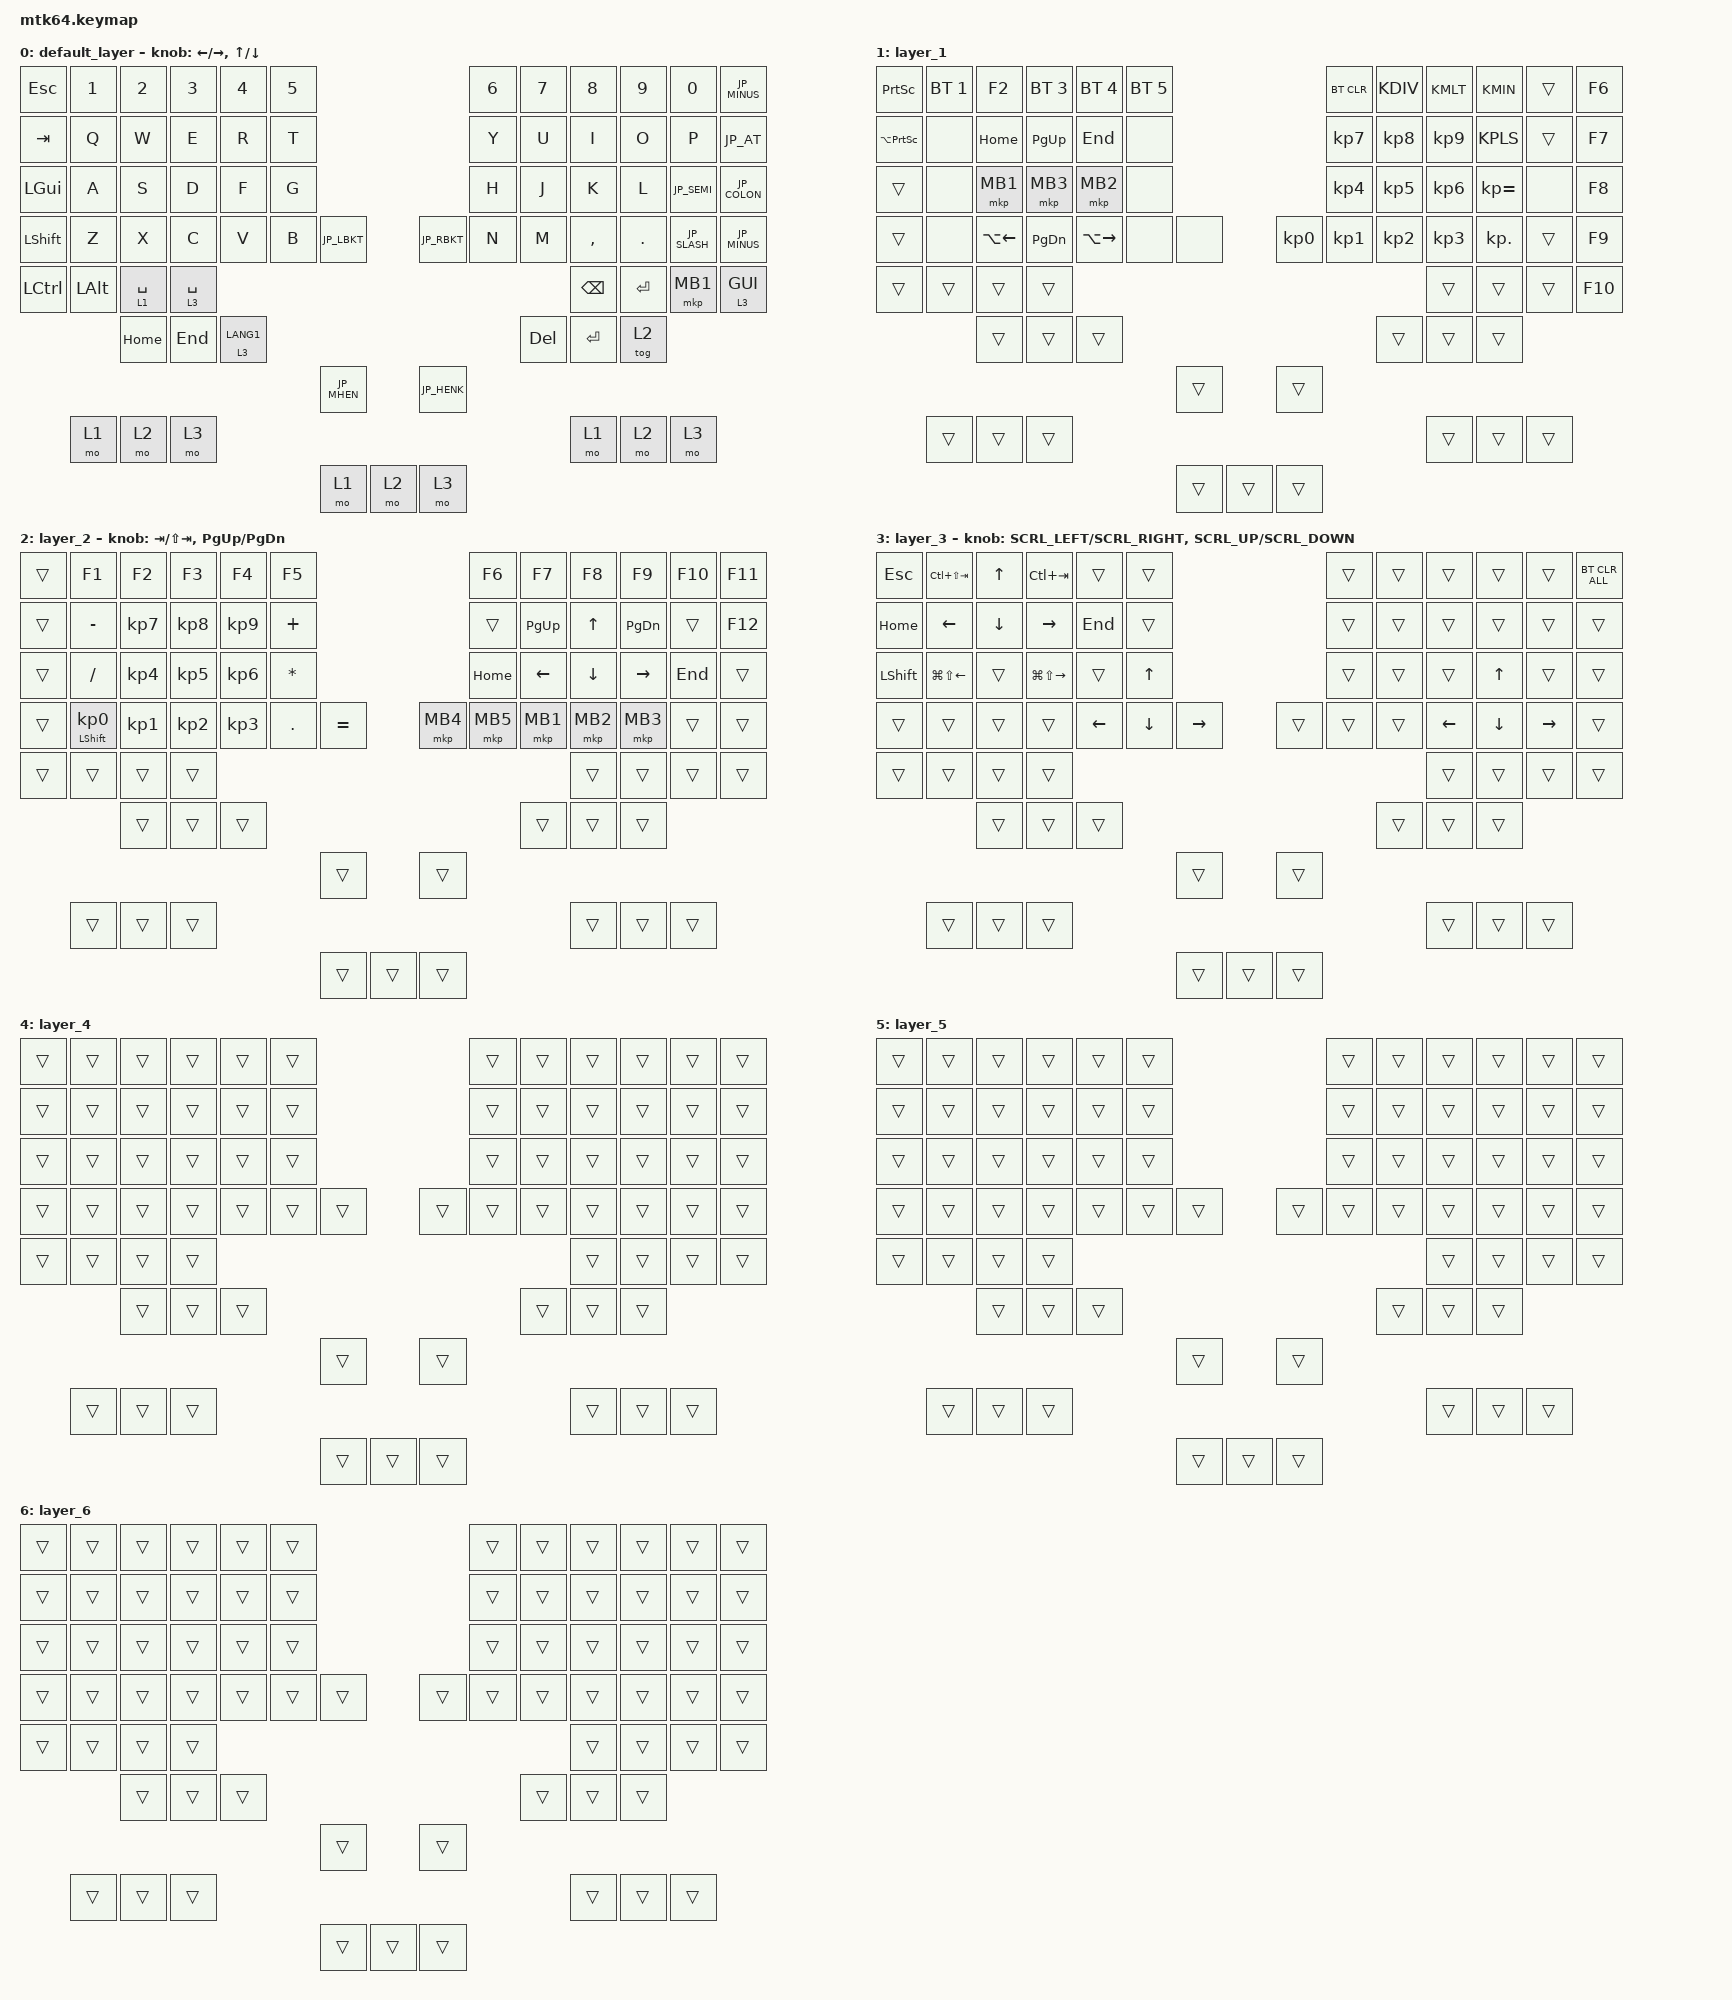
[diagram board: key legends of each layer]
#include <behaviors.dtsi>
#include <dt-bindings/zmk/bt.h>
#include <dt-bindings/zmk/keys.h>
#include <dt-bindings/zmk/pointing.h>
#include <input/processors.dtsi>
#include "keycode_japanese.h"

// スクロール量の設定
#undef ZMK_POINTING_DEFAULT_SCRL_VAL
#define ZMK_POINTING_DEFAULT_SCRL_VAL 60

&mt {
    flavor = "balanced";
    quick-tap-ms = <0>;
};

/*
&mkp_input_listener {
    input-processors = <&zip_temp_layer 6 5000>;
};
*/

/ {
    behaviors {
        // 垂直スクロール用のbehaviorの設定
        scroll_up_down: behavior_sensor_rotate_mouse_wheel_up_down {
            compatible = "zmk,behavior-sensor-rotate-var";
            #sensor-binding-cells = <2>;
            bindings = <&msc>, <&msc>;
            tap-ms = <20>; // スクロールのタップ時間
        };
        // 水平スクロール用のbehaviorの設定
        scroll_left_right: behavior_sensor_rotate_mouse_wheel_left_right {
            compatible = "zmk,behavior-sensor-rotate-var";
            #sensor-binding-cells = <2>;
            bindings = <&msc>, <&msc>;
            tap-ms = <20>; // スクロールのタップ時間
        };
    };
};

/ {

    keymap {
        compatible = "zmk,keymap";

        default_layer {
            bindings = <
&kp ESC   &kp N1 &kp N2 &kp N3   &kp N4   &kp N5                                &kp N6 &kp N7   &kp N8    &kp N9  &kp N0       &kp JP_MINUS
&kp TAB   &kp Q  &kp W  &kp E    &kp R    &kp T                                 &kp Y  &kp U    &kp I     &kp O   &kp P        &kp JP_AT
&kp LGUI &kp A  &kp S  &kp D    &kp F    &kp G                                 &kp H  &kp J    &kp K     &kp L   &kp JP_SEMI  &kp JP_COLON
&kp LSHFT &kp Z  &kp X  &kp C    &kp V    &kp B  &kp JP_LBKT        &kp JP_RBKT &kp N  &kp M    &kp COMMA &kp DOT &kp JP_SLASH &kp JP_MINUS
&kp LCTRL  &kp LALT               &lt 1 SPACE     &lt 3 SPACE        &kp BSPC    &kp ENTER                         &mkp MB1 &lt 3 GUI
                 &kp HOME &kp END                &lt 3 LANG1        &kp DEL                 &kp ENTER &tog 2
                                                 &kp JP_MHEN          &kp JP_HENK
          &mo 1  &mo 2  &mo 3                                                                   &mo 1     &mo 2   &mo 3
                                                 &mo 1    &mo 2     &mo 3  
            >;

            sensor-bindings = <
                &inc_dec_kp LEFT_ARROW RIGHT_ARROW
                &inc_dec_kp UP_ARROW   DOWN_ARROW
            >;
        };

        layer_1 {
            bindings = <
&kp PRINTSCREEN  &bt BT_SEL 1  &kp F2  &bt BT_SEL 3  &bt BT_SEL 4  &bt BT_SEL 5
                                                                    &bt BT_CLR  &kp KDIV  &kp KMLT  &kp KMIN  &trans  &kp F6
&kp LA(PRINTSCREEN)  &none                   &kp HOME  &kp PG_UP  &kp END  &none                                    &kp KP_N7            &kp KP_N8          &kp KP_N9    &kp KPLS             &trans                &kp F7  
&trans  &none                   &mkp MB1  &mkp MB3  &mkp MB2  &none                                &kp KP_N4          &kp KP_N5     &kp KP_N6  &kp KP_EQUAL       &none               &kp F8  
&trans  &none  &kp LA(LEFT)  &kp PG_DN  &kp LA(RIGHT)  &none    &none      &kp KP_N0       &kp KP_N1          &kp KP_N2           &kp KP_N3        &kp KP_DOT              &trans                &kp F9  
&trans  &trans                                                                         &trans        &trans         &trans         &trans                                                                     &trans                &kp F10
                                    &trans           &trans                                          &trans         &trans                                              &trans          &trans
                                                                                                     &trans         &trans
        &trans                      &trans           &trans                                                                                                             &trans          &trans                &trans
                                                                                                     &trans &trans  &trans 
            >;
        };

        layer_2 {
            bindings = <
&trans  &kp F1                      &kp F2           &kp F3           &kp F4           &kp F5                                      &kp F6            &kp F7             &kp F8          &kp F9                &kp F10               &kp F11
&trans  &kp MINUS                   &kp KP_NUMBER_7  &kp KP_NUMBER_8  &kp KP_NUMBER_9  &kp PLUS                                    &trans            &kp PG_UP          &kp UP_ARROW    &kp PG_DN             &trans                &kp F12  
&trans  &kp SLASH                   &kp KP_NUMBER_4  &kp KP_NUMBER_5  &kp KP_NUMBER_6  &kp ASTERISK                                &kp HOME          &kp LEFT_ARROW     &kp DOWN_ARROW  &kp RIGHT_ARROW       &kp END               &trans  
&trans  &mt LEFT_SHIFT KP_NUMBER_0  &kp KP_NUMBER_1  &kp KP_NUMBER_2  &kp KP_NUMBER_3  &kp PERIOD    &kp EQUAL      &mkp MB4       &mkp MB5          &mkp MB1           &mkp MB2        &mkp MB3              &trans                &trans  
&trans  &trans                                                                         &trans        &trans         &trans         &trans                                                                     &trans                &trans
                                    &trans           &trans                                          &trans         &trans                                              &trans          &trans
                                                                                                     &trans         &trans
        &trans                      &trans           &trans                                                                                                             &trans          &trans                &trans
                                                                                                     &trans &trans  &trans 
            >;
            sensor-bindings = <
                &inc_dec_kp TAB LS(TAB) 
                &inc_dec_kp PG_UP PG_DN
            >;
        };

        layer_3 {
            bindings = <
&kp ESCAPE  &kp LC(LS(TAB))  &kp UP_ARROW  &kp LC(TAB)  &trans  &trans  &trans  &trans  &trans  &trans  &trans  &bt BT_CLR_ALL
&kp HOME  &kp LEFT_ARROW  &kp DOWN_ARROW  &kp RIGHT_ARROW  &kp END  &trans  &trans  &trans  &trans  &trans  &trans  &trans
&kp LEFT_SHIFT  &kp LG(LS(LEFT_ARROW))  &trans  &kp LG(LS(RIGHT_ARROW))  &trans  &kp UP  &trans  &trans  &trans  &kp UP  &trans  &trans
&trans  &trans  &trans  &trans  &kp LEFT  &kp DOWN  &kp RIGHT  &trans  &trans  &trans  &kp LEFT  &kp DOWN  &kp RIGHT  &trans
&trans  &trans  &trans  &trans  &trans  &trans  &trans  &trans
&trans  &trans  &trans  &trans  &trans  &trans
&trans  &trans
&trans  &trans  &trans  &trans  &trans  &trans
&trans  &trans  &trans
>;
            sensor-bindings = <
                &scroll_left_right SCRL_LEFT SCRL_RIGHT
                &scroll_up_down SCRL_UP SCRL_DOWN
            >;
        };

        layer_4 {
            bindings = <
&trans  &trans  &trans  &trans  &trans  &trans                      &trans  &trans  &trans  &trans  &trans  &trans
&trans  &trans  &trans  &trans  &trans  &trans                      &trans  &trans  &trans  &trans  &trans  &trans
&trans  &trans  &trans  &trans  &trans  &trans                      &trans  &trans  &trans  &trans  &trans  &trans
&trans  &trans  &trans  &trans  &trans  &trans  &trans      &trans  &trans  &trans  &trans  &trans  &trans  &trans
&trans  &trans                          &trans  &trans      &trans  &trans                          &trans  &trans
                &trans  &trans                  &trans      &trans                  &trans  &trans
                                                &trans      &trans
        &trans  &trans  &trans                                                      &trans  &trans  &trans
                                               &trans &trans &trans
            >;
        };

        layer_5 {
            bindings = <
&trans  &trans  &trans  &trans  &trans  &trans                      &trans  &trans  &trans  &trans  &trans  &trans
&trans  &trans  &trans  &trans  &trans  &trans                      &trans  &trans  &trans  &trans  &trans  &trans
&trans  &trans  &trans  &trans  &trans  &trans                      &trans  &trans  &trans  &trans  &trans  &trans
&trans  &trans  &trans  &trans  &trans  &trans  &trans      &trans  &trans  &trans  &trans  &trans  &trans  &trans
&trans  &trans                          &trans  &trans      &trans  &trans                          &trans  &trans
                &trans  &trans                  &trans      &trans                  &trans  &trans
                                                &trans      &trans
        &trans  &trans  &trans                                                      &trans  &trans  &trans
                                               &trans &trans &trans
            >;
        };

        layer_6 {
            bindings = <
&trans  &trans  &trans  &trans  &trans  &trans                      &trans  &trans  &trans  &trans  &trans  &trans
&trans  &trans  &trans  &trans  &trans  &trans                      &trans  &trans  &trans  &trans  &trans  &trans
&trans  &trans  &trans  &trans  &trans  &trans                      &trans  &trans  &trans  &trans  &trans  &trans
&trans  &trans  &trans  &trans  &trans  &trans  &trans      &trans  &trans  &trans  &trans  &trans  &trans  &trans
&trans  &trans                          &trans  &trans      &trans  &trans                          &trans  &trans
                &trans  &trans                  &trans      &trans                  &trans  &trans
                                                &trans      &trans
        &trans  &trans  &trans                                                      &trans  &trans  &trans
                                               &trans &trans &trans 
            >;
        };
    };
};
